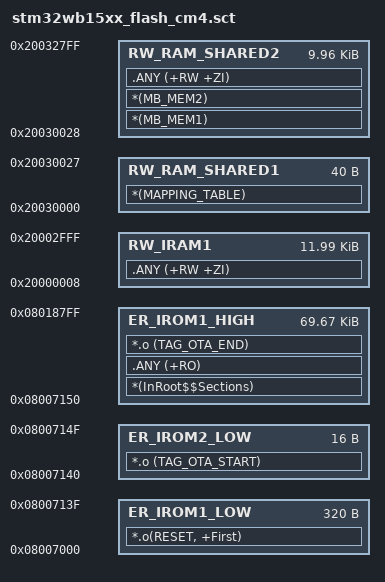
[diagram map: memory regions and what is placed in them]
; *************************************************************
; *** Scatter-Loading Description File generated by uVision ***
; *************************************************************

LR_IROM1 0x08007000 0x140{    ; load region size_region
  ER_IROM1_LOW 0x08007000 0x140  {  ; load address = execution address
 *.o(RESET, +First)
  }  
 }

LR_IROM2 0x08007140 0x10{    ; load region size_region  
  ER_IROM2_LOW 0x08007140 0x10  {
 *.o (TAG_OTA_START) 
  }  
 }
 
LR_IROM3 0x08007150 0x116B0{
  ER_IROM1_HIGH 0x08007150 0x116B0 {  ; load address = execution address	
  *(InRoot$$Sections)
  .ANY (+RO)  
  *.o (TAG_OTA_END)	
  }
  
  RW_IRAM1 0x20000008 0x2FF8  {  ; RW data
  .ANY (+RW +ZI)
  }

  RW_RAM_SHARED1 0x20030000 0x28  {  ; RW data 
  *(MAPPING_TABLE)
  }
  RW_RAM_SHARED2 0x20030028 0x27D8  { ; RW data      
  *(MB_MEM1)
  *(MB_MEM2)
  .ANY (+RW +ZI)
  }
 }
